VERSION "created by canmatrix"

NS_ :

BS_:

BU_: User ADM_PC_LL25 ADM_PC_BC25 ADM_PC_BP25 ADM_PC_BI25

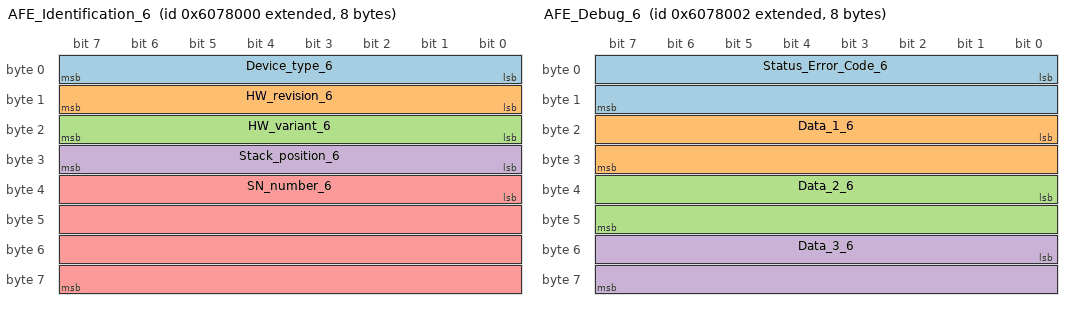
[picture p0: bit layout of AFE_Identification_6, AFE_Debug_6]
BO_ 2248638464 AFE_Identification_6: 8 ADM_PC_BP25
 SG_ Device_type_6 : 0|8@1+ (1,0) [0|255] "" Vector__XXX
 SG_ HW_revision_6 : 8|8@1+ (1,0) [0|255] "" Vector__XXX
 SG_ HW_variant_6 : 16|8@1+ (1,0) [0|255] "" Vector__XXX
 SG_ Stack_position_6 : 24|8@1+ (1,0) [0|255] "" Vector__XXX
 SG_ SN_number_6 : 32|32@1+ (1,0) [0|4294967295] "" Vector__XXX

BO_ 2248638465 AFE_FwInfo_6: 8 ADM_PC_BP25
 SG_ FW_info_mux_6 M : 56|8@1+ (1,0) [0|255] "" Vector__XXX
 SG_ FW_revision_0_6 m0 : 0|8@1+ (1,0) [0|255] "" Vector__XXX
 SG_ FW_revision_1_6 m0 : 8|8@1+ (1,0) [0|255] "" Vector__XXX
 SG_ FW_revision_2_6 m0 : 16|8@1+ (1,0) [0|255] "" Vector__XXX
 SG_ FW_revision_3_6 m0 : 24|8@1+ (1,0) [0|255] "" Vector__XXX
 SG_ FW_revision_4_6 m0 : 32|8@1+ (1,0) [0|255] "" Vector__XXX
 SG_ FW_revision_5_6 m0 : 40|8@1+ (1,0) [0|255] "" Vector__XXX
 SG_ FW_revision_6_6 m0 : 48|8@1+ (1,0) [0|255] "" Vector__XXX
 SG_ FW_revision_7_6 m1 : 0|8@1+ (1,0) [0|255] "" Vector__XXX
 SG_ FW_revision_8_6 m1 : 8|8@1+ (1,0) [0|255] "" Vector__XXX
 SG_ FW_revision_9_6 m1 : 16|8@1+ (1,0) [0|255] "" Vector__XXX
 SG_ FW_revision_10_6 m1 : 24|8@1+ (1,0) [0|255] "" Vector__XXX
 SG_ FW_revision_11_6 m1 : 32|8@1+ (1,0) [0|255] "" Vector__XXX
 SG_ FW_revision_12_6 m1 : 40|8@1+ (1,0) [0|255] "" Vector__XXX
 SG_ FW_revision_13_6 m1 : 48|8@1+ (1,0) [0|255] "" Vector__XXX
 SG_ FW_datecode_0_6 m2 : 0|8@1+ (1,0) [0|255] "" Vector__XXX
 SG_ FW_datecode_1_6 m2 : 8|8@1+ (1,0) [0|255] "" Vector__XXX
 SG_ FW_datecode_2_6 m2 : 16|8@1+ (1,0) [0|255] "" Vector__XXX
 SG_ FW_datecode_3_6 m2 : 24|8@1+ (1,0) [0|255] "" Vector__XXX
 SG_ FW_datecode_4_6 m2 : 32|8@1+ (1,0) [0|255] "" Vector__XXX
 SG_ FW_datecode_5_6 m2 : 40|8@1+ (1,0) [0|255] "" Vector__XXX
 SG_ FW_datecode_6_6 m2 : 48|8@1+ (1,0) [0|255] "" Vector__XXX
 SG_ FW_datecode_7_6 m3 : 0|8@1+ (1,0) [0|255] "" Vector__XXX
 SG_ FW_datecode_8_6 m3 : 8|8@1+ (1,0) [0|255] "" Vector__XXX
 SG_ FW_datecode_9_6 m3 : 16|8@1+ (1,0) [0|255] "" Vector__XXX
 SG_ FW_datecode_10_6 m3 : 24|8@1+ (1,0) [0|255] "" Vector__XXX
 SG_ FW_datecode_11_6 m3 : 32|8@1+ (1,0) [0|255] "" Vector__XXX
 SG_ FW_datecode_12_6 m3 : 40|8@1+ (1,0) [0|255] "" Vector__XXX
 SG_ FW_datecode_13_6 m3 : 48|8@1+ (1,0) [0|255] "" Vector__XXX

BO_ 2248638477 _AFE_Boot_FwInfo_6: 8 ADM_PC_BP25
 SG_ Boot_FW_info_mux_6 M : 56|8@1+ (1,0) [0|255] "" Vector__XXX
 SG_ FW_revision_0_6 m0 : 0|8@1+ (1,0) [0|255] "" Vector__XXX
 SG_ FW_revision_1_6 m0 : 8|8@1+ (1,0) [0|255] "" Vector__XXX
 SG_ FW_revision_2_6 m0 : 16|8@1+ (1,0) [0|255] "" Vector__XXX
 SG_ FW_revision_3_6 m0 : 24|8@1+ (1,0) [0|255] "" Vector__XXX
 SG_ FW_revision_4_6 m0 : 32|8@1+ (1,0) [0|255] "" Vector__XXX
 SG_ FW_revision_5_6 m0 : 40|8@1+ (1,0) [0|255] "" Vector__XXX
 SG_ FW_revision_6_6 m0 : 48|8@1+ (1,0) [0|255] "" Vector__XXX
 SG_ FW_revision_7_6 m1 : 0|8@1+ (1,0) [0|255] "" Vector__XXX
 SG_ FW_revision_8_6 m1 : 8|8@1+ (1,0) [0|255] "" Vector__XXX
 SG_ FW_revision_9_6 m1 : 16|8@1+ (1,0) [0|255] "" Vector__XXX
 SG_ FW_revision_10_6 m1 : 24|8@1+ (1,0) [0|255] "" Vector__XXX
 SG_ FW_revision_11_6 m1 : 32|8@1+ (1,0) [0|255] "" Vector__XXX
 SG_ FW_revision_12_6 m1 : 40|8@1+ (1,0) [0|255] "" Vector__XXX
 SG_ FW_revision_13_6 m1 : 48|8@1+ (1,0) [0|255] "" Vector__XXX
 SG_ FW_datecode_0_6 m2 : 0|8@1+ (1,0) [0|255] "" Vector__XXX
 SG_ FW_datecode_1_6 m2 : 8|8@1+ (1,0) [0|255] "" Vector__XXX
 SG_ FW_datecode_2_6 m2 : 16|8@1+ (1,0) [0|255] "" Vector__XXX
 SG_ FW_datecode_3_6 m2 : 24|8@1+ (1,0) [0|255] "" Vector__XXX
 SG_ FW_datecode_4_6 m2 : 32|8@1+ (1,0) [0|255] "" Vector__XXX
 SG_ FW_datecode_5_6 m2 : 40|8@1+ (1,0) [0|255] "" Vector__XXX
 SG_ FW_datecode_6_6 m2 : 48|8@1+ (1,0) [0|255] "" Vector__XXX
 SG_ FW_datecode_7_6 m3 : 0|8@1+ (1,0) [0|255] "" Vector__XXX
 SG_ FW_datecode_8_6 m3 : 8|8@1+ (1,0) [0|255] "" Vector__XXX
 SG_ FW_datecode_9_6 m3 : 16|8@1+ (1,0) [0|255] "" Vector__XXX
 SG_ FW_datecode_10_6 m3 : 24|8@1+ (1,0) [0|255] "" Vector__XXX
 SG_ FW_datecode_11_6 m3 : 32|8@1+ (1,0) [0|255] "" Vector__XXX
 SG_ FW_datecode_12_6 m3 : 40|8@1+ (1,0) [0|255] "" Vector__XXX
 SG_ FW_datecode_13_6 m3 : 48|8@1+ (1,0) [0|255] "" Vector__XXX

BO_ 2248638466 AFE_Debug_6: 8 ADM_PC_BP25
 SG_ Status_Error_Code_6 : 0|16@1+ (1,0) [0|65535] "" Vector__XXX
 SG_ Data_1_6 : 16|16@1+ (1,0) [0|65535] "" Vector__XXX
 SG_ Data_2_6 : 32|16@1+ (1,0) [0|65535] "" Vector__XXX
 SG_ Data_3_6 : 48|16@1+ (1,0) [0|65535] "" Vector__XXX

BO_ 2248638471 AFE_Status_6: 8 ADM_PC_BP25
 SG_ Running_6 : 0|1@1+ (1,0) [0|1] "" Vector__XXX
 SG_ PWM_6 : 1|1@1+ (1,0) [0|1] "" Vector__XXX
 SG_ Current_dc_loop_mode_6 : 2|1@1+ (1,0) [0|1] "" Vector__XXX
 SG_ Current_ac_loop_mode_6 : 3|1@1+ (1,0) [0|1] "" Vector__XXX
 SG_ Buck_6 : 5|1@1+ (1,0) [0|1] "" Vector__XXX
 SG_ Boost_6 : 6|1@1+ (1,0) [0|1] "" Vector__XXX
 SG_ Precharge_dc_buck_mode_6 : 7|1@1+ (1,0) [0|1] "" Vector__XXX
 SG_ Precharge_dc_boost_mode_6 : 8|1@1+ (1,0) [0|1] "" Vector__XXX
 SG_ Rectifier_3ph_6 : 9|1@1+ (1,0) [0|1] "" Vector__XXX
 SG_ Stack_mode_6 : 10|1@1+ (1,0) [0|1] "" Vector__XXX
 SG_ Master_6 : 11|1@1+ (1,0) [0|1] "" Vector__XXX
 SG_ Slave_6 : 12|1@1+ (1,0) [0|1] "" Vector__XXX
 SG_ Inverter_1ph_6 : 13|1@1+ (1,0) [0|1] "" Vector__XXX
 SG_ Boost_Neutral_6 : 14|1@1+ (1,0) [0|1] "" Vector__XXX
 SG_ Rectifier_1ph_6 : 15|1@1+ (1,0) [0|1] "" Vector__XXX
 SG_ Inverter_3ph_6 : 16|1@1+ (1,0) [0|1] "" Vector__XXX
 SG_ Ready_6 : 17|1@1+ (1,0) [0|1] "" Vector__XXX
 SG_ Inverter_1ph_Sync_6 : 18|1@1+ (1,0) [0|1] "" Vector__XXX
 SG_ Neutral_6 : 19|1@1+ (1,0) [0|1] "" Vector__XXX
 SG_ Rectifier_1ph_Buck_6 : 20|1@1+ (1,0) [0|1] "" Vector__XXX
 SG_ Inverter_1ph_Boost_6 : 21|1@1+ (1,0) [0|1] "" Vector__XXX
 SG_ Rectifier_distributed_6 : 22|1@1+ (1,0) [0|1] "" Vector__XXX
 SG_ MPPT_buck_6 : 23|1@1+ (1,0) [0|1] "" Vector__XXX
 SG_ MPPT_boost_6 : 24|1@1+ (1,0) [0|1] "" Vector__XXX
 SG_ Buck_2p_float_6 : 25|1@1+ (1,0) [0|1] "" Vector__XXX
 SG_ Inverter_1ph_Distributed_6 : 26|1@1+ (1,0) [0|1] "" Vector__XXX

BO_ 2248638470 AFE_Faults_6: 3 ADM_PC_BP25
 SG_ Protection_trip_internal_6 : 0|1@1+ (1,0) [0|1] "" Vector__XXX
 SG_ Protection_trip_external_6 : 1|1@1+ (1,0) [0|1] "" Vector__XXX
 SG_ Phase_U_overcurrent_6 : 2|1@1+ (1,0) [0|1] "" Vector__XXX
 SG_ Phase_U_overvoltage_6 : 3|1@1+ (1,0) [0|1] "" Vector__XXX
 SG_ Phase_U_undervoltage_6 : 4|1@1+ (1,0) [0|1] "" Vector__XXX
 SG_ Phase_V_overvoltage_6 : 5|1@1+ (1,0) [0|1] "" Vector__XXX
 SG_ Phase_V_undervoltage_6 : 6|1@1+ (1,0) [0|1] "" Vector__XXX
 SG_ Phase_V_overcurrent_6 : 7|1@1+ (1,0) [0|1] "" Vector__XXX
 SG_ Phase_W_overvoltage_6 : 8|1@1+ (1,0) [0|1] "" Vector__XXX
 SG_ Phase_W_undervoltage_6 : 9|1@1+ (1,0) [0|1] "" Vector__XXX
 SG_ Phase_W_overcurrent_6 : 10|1@1+ (1,0) [0|1] "" Vector__XXX
 SG_ DC_undervoltage_6 : 11|1@1+ (1,0) [0|1] "" Vector__XXX
 SG_ DC_overvoltage_6 : 12|1@1+ (1,0) [0|1] "" Vector__XXX
 SG_ MOSFET_overtemperature_6 : 13|1@1+ (1,0) [0|1] "" Vector__XXX
 SG_ Inductor_overtemperature_6 : 14|1@1+ (1,0) [0|1] "" Vector__XXX
 SG_ Keep_Alive_not_served_6 : 15|1@1+ (1,0) [0|1] "" Vector__XXX
 SG_ PLL_not_locked_6 : 16|1@1+ (1,0) [0|1] "" Vector__XXX
 SG_ NFO_6 : 20|1@1+ (1,0) [0|1] "" Vector__XXX
 SG_ Measurement_system_failure_6 : 21|1@1+ (1,0) [0|1] "" Vector__XXX
 SG_ EEPROM_failure_6 : 22|1@1+ (1,0) [0|1] "" Vector__XXX
 SG_ System_6 : 23|1@1+ (1,0) [0|1] "" Vector__XXX

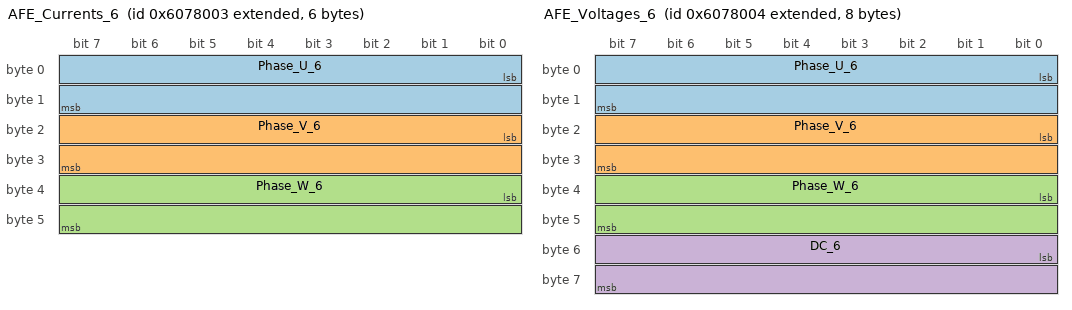
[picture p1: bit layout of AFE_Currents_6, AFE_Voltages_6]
BO_ 2248638467 AFE_Currents_6: 6 ADM_PC_BP25
 SG_ Phase_U_6 : 0|16@1- (0.01,0) [-327.68|327.67] "A" Vector__XXX
 SG_ Phase_V_6 : 16|16@1- (0.01,0) [-327.68|327.67] "A" Vector__XXX
 SG_ Phase_W_6 : 32|16@1- (0.01,0) [-327.68|327.67] "A" Vector__XXX

BO_ 2248638480 AFE_DC_Bus_current_6: 2 ADM_PC_BP25
 SG_ Bus_current_6 : 0|16@1- (0.01,0) [-327.68|327.67] "A" Vector__XXX

BO_ 2248638478 _AFE_Broadcast_6: 8 ADM_PC_BP25
 SG_ Diagnostics_Index_6 M : 56|8@1+ (1,0) [0|255] "" Vector__XXX
 SG_ Phase_U_6 m1 : 8|16@1- (0.01,0) [-327.68|327.67] "A" ADM_PC_BP25
 SG_ Phase_V_6 m1 : 24|16@1- (0.01,0) [-327.68|327.67] "A" ADM_PC_BP25
 SG_ Phase_W_6 m1 : 40|16@1- (0.01,0) [-327.68|327.67] "A" ADM_PC_BP25
 SG_ Stack_position_6 : 0|5@1+ (1,0) [0|31] "" ADM_PC_BP25
 SG_ Group_ID_6 : 5|3@1+ (1,0) [0|7] "" ADM_PC_BP25

BO_ 2248638468 AFE_Voltages_6: 8 ADM_PC_BP25
 SG_ Phase_U_6 : 0|16@1- (0.1,0) [-3276.8|3276.7] "V" Vector__XXX
 SG_ Phase_V_6 : 16|16@1- (0.1,0) [-3276.8|3276.7] "V" Vector__XXX
 SG_ Phase_W_6 : 32|16@1- (0.1,0) [-3276.8|3276.7] "V" Vector__XXX
 SG_ DC_6 : 48|16@1- (0.1,0) [-3276.8|3276.7] "V" Vector__XXX

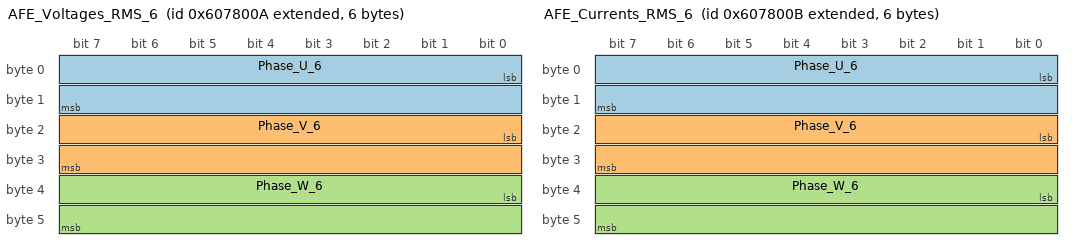
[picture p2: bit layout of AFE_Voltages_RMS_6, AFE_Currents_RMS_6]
BO_ 2248638474 AFE_Voltages_RMS_6: 6 ADM_PC_BP25
 SG_ Phase_U_6 : 0|16@1+ (0.1,0) [0|6553.5] "V" Vector__XXX
 SG_ Phase_V_6 : 16|16@1+ (0.1,0) [0|6553.5] "V" Vector__XXX
 SG_ Phase_W_6 : 32|16@1+ (0.1,0) [0|6553.5] "V" Vector__XXX

BO_ 2248638475 AFE_Currents_RMS_6: 6 ADM_PC_BP25
 SG_ Phase_U_6 : 0|16@1+ (0.01,0) [0.00|655.35] "A" Vector__XXX
 SG_ Phase_V_6 : 16|16@1+ (0.01,0) [0.00|655.35] "A" Vector__XXX
 SG_ Phase_W_6 : 32|16@1+ (0.01,0) [0.00|655.35] "A" Vector__XXX

BO_ 2248638476 AFE_Mains_6: 4 ADM_PC_BP25
 SG_ Frequency_6 : 0|16@1+ (0.01,0) [0.00|655.35] "Hz" Vector__XXX
 SG_ Phase_6 : 16|16@1- (0.1,0) [-3276.8|3276.7] "Deg." Vector__XXX

BO_ 2248638469 AFE_Temperatures_6: 4 ADM_PC_BP25
 SG_ Temp_Bridge_6 : 0|16@1- (0.01,0) [-327.68|327.67] "°C" Vector__XXX
 SG_ Temp_Inductors_6 : 16|16@1- (0.01,0) [-327.68|327.67] "°C" Vector__XXX

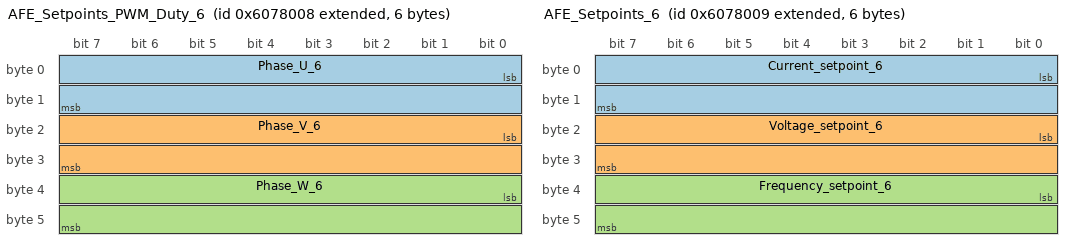
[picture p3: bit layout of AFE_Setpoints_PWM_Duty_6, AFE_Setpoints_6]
BO_ 2248638472 AFE_Setpoints_PWM_Duty_6: 6 ADM_PC_BP25
 SG_ Phase_U_6 : 0|16@1+ (0.001525902,0) [0E-009|99.999987570] "%" Vector__XXX
 SG_ Phase_V_6 : 16|16@1+ (0.001525902,0) [0E-009|99.999987570] "%" Vector__XXX
 SG_ Phase_W_6 : 32|16@1+ (0.001525902,0) [0E-009|99.999987570] "%" Vector__XXX

BO_ 2248638473 AFE_Setpoints_6: 6 ADM_PC_BP25
 SG_ Current_setpoint_6 : 0|16@1- (0.01,0) [-327.68|327.67] "A" Vector__XXX
 SG_ Voltage_setpoint_6 : 16|16@1+ (0.1,0) [0|6553.5] "V" Vector__XXX
 SG_ Frequency_setpoint_6 : 32|16@1+ (0.01,0) [0.00|655.35] "Hz" Vector__XXX

BO_ 2248605792 AFE_Keep_Alive_6: 1 User
 SG_ Keep_Alive_Enable_6 : 0|1@1+ (1,0) [0|1] "" ADM_PC_BP25

BO_ 2248605760 AFE_Mode_Control_6: 8 User
 SG_ Converter_ON_6 : 0|1@1+ (1,0) [0|1] "" ADM_PC_BP25
 SG_ PWM_ON_6 : 1|1@1+ (1,0) [0|1] "" ADM_PC_BP25
 SG_ DC_Current_feedback_ON_6 : 2|1@1+ (1,0) [0|1] "" ADM_PC_BP25
 SG_ AC_Current_feedback_ON_6 : 3|1@1+ (1,0) [0|1] "" ADM_PC_BP25
 SG_ Buck_ON_6 : 5|1@1+ (1,0) [0|1] "" ADM_PC_BP25
 SG_ Boost_ON_6 : 6|1@1+ (1,0) [0|1] "" ADM_PC_BP25
 SG_ Rectifier_3ph_ON_6 : 9|1@1+ (1,0) [0|1] "" ADM_PC_BP25
 SG_ Inverter_1ph_ON_6 : 10|1@1+ (1,0) [0|1] "" ADM_PC_BP25
 SG_ Rectifier_1ph_ON_6 : 11|1@1+ (1,0) [0|1] "" ADM_PC_BP25
 SG_ Boost_Neutral_ON_6 : 12|1@1+ (1,0) [0|1] "" ADM_PC_BP25
 SG_ Inverter_3ph_ON_6 : 13|1@1+ (1,0) [0|1] "" ADM_PC_BP25
 SG_ Inverter_1ph_Sync_ON_6 : 14|1@1+ (1,0) [0|1] "" ADM_PC_BP25
 SG_ Neutral_ON_6 : 15|1@1+ (1,0) [0|1] "" ADM_PC_BP25
 SG_ Rectifier_1ph_Buck_ON_6 : 16|1@1+ (1,0) [0|1] "" ADM_PC_BP25
 SG_ Inverter_1ph_Boost_ON_6 : 17|1@1+ (1,0) [0|1] "" ADM_PC_BP25
 SG_ Rectifier_Distributed_ON_6 : 18|1@1+ (1,0) [0|1] "" ADM_PC_BP25
 SG_ MPPT_buck_ON_6 : 19|1@1+ (1,0) [0|1] "" ADM_PC_BP25
 SG_ MPPT_boost_ON_6 : 20|1@1+ (1,0) [0|1] "" ADM_PC_BP25
 SG_ Buck_2p_float_ON_6 : 21|1@1+ (1,0) [0|1] "" ADM_PC_BP25
 SG_ Inverter_1ph_Distributed_ON_6 : 22|1@1+ (1,0) [0|1] "" ADM_PC_BP25

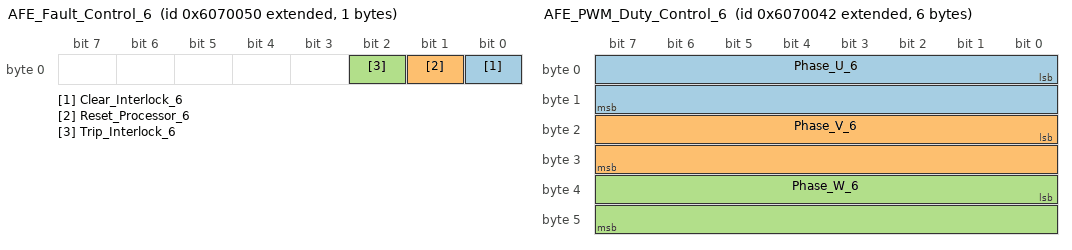
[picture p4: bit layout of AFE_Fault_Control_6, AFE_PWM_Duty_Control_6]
BO_ 2248605776 AFE_Fault_Control_6: 1 User
 SG_ Clear_Interlock_6 : 0|1@1+ (1,0) [0|1] "" ADM_PC_BP25
 SG_ Reset_Processor_6 : 1|1@1+ (1,0) [0|1] "" ADM_PC_BP25
 SG_ Trip_Interlock_6 : 2|1@1+ (1,0) [0|1] "" ADM_PC_BP25

BO_ 2248605761 AFE_Reactive_Current_Setpoint_Co: 2 User
 SG_ Reactive_current_setpoint_6 : 0|16@1- (0.01,0) [-150|150] "A" ADM_PC_BP25

BO_ 2248605762 AFE_PWM_Duty_Control_6: 6 User
 SG_ Phase_U_6 : 0|16@1+ (0.001525902,0) [0E-009|99.999987570] "%" ADM_PC_BP25
 SG_ Phase_V_6 : 16|16@1+ (0.001525902,0) [0E-009|99.999987570] "%" ADM_PC_BP25
 SG_ Phase_W_6 : 32|16@1+ (0.001525902,0) [0E-009|99.999987570] "%" ADM_PC_BP25

BO_ 2248605763 AFE_Current_Setpoint_Control_6: 2 User
 SG_ Current_setpoint_6 : 0|16@1- (0.01,0) [-150|150] "A" ADM_PC_BP25

BO_ 2248605764 AFE_Voltage_Setpoint_Control_6: 2 User
 SG_ Voltage_setpoint_6 : 0|16@1+ (0.1,0) [0|1500] "V" ADM_PC_BP25

BO_ 2248605768 AFE_Frequency_Setpoint_Control_6: 2 User
 SG_ Frequency_setpoint_6 : 0|16@1+ (0.01,0) [40|70] "Hz" ADM_PC_BP25

BO_ 2248605769 AFE_Phase_Setpoint_Control_6: 2 User
 SG_ Phase_setpoint_6 : 0|16@1+ (1,0) [0|360] "deg" ADM_PC_BP25

BO_ 2248605808 AFE_Rectifier_Setpoint_Control_6: 8 User
 SG_ Voltage_setpoint_2_6 : 0|16@1+ (0.1,0) [0|1500] "V" ADM_PC_BP25
 SG_ Current_setpoint_2_6 : 16|16@1- (0.01,0) [-150|150] "A" ADM_PC_BP25

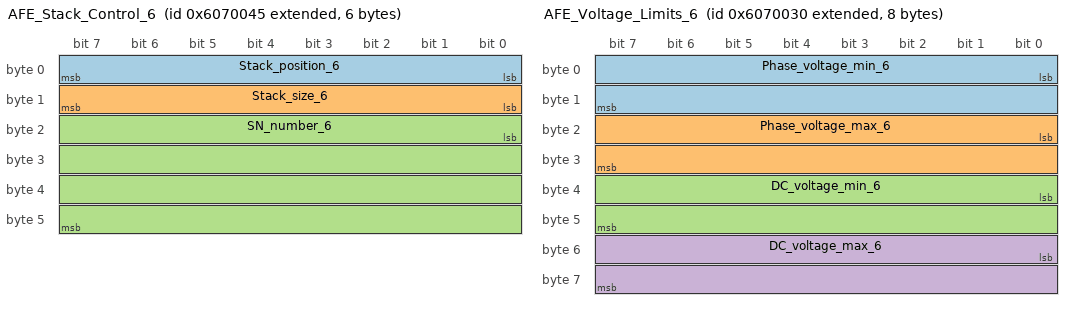
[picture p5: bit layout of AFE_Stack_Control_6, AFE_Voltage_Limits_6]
BO_ 2248605765 AFE_Stack_Control_6: 6 User
 SG_ Stack_position_6 : 0|8@1+ (1,0) [0|255] "" ADM_PC_BP25
 SG_ Stack_size_6 : 8|8@1+ (1,0) [0|255] "" ADM_PC_BP25
 SG_ SN_number_6 : 16|32@1+ (1,0) [0|4294967295] "" ADM_PC_BP25

BO_ 2248605744 AFE_Voltage_Limits_6: 8 User
 SG_ Phase_voltage_min_6 : 0|16@1- (0.1,0) [0|3276.7] "V" ADM_PC_BP25
 SG_ Phase_voltage_max_6 : 16|16@1- (0.1,0) [-3276.8|850] "V" ADM_PC_BP25
 SG_ DC_voltage_min_6 : 32|16@1- (0.1,0) [0|3276.7] "V" ADM_PC_BP25
 SG_ DC_voltage_max_6 : 48|16@1- (0.1,0) [-3276.8|850] "V" ADM_PC_BP25

BO_ 2248605745 AFE_Current_Limits_6: 4 User
 SG_ Phase_current_min_6 : 0|16@1- (0.01,0) [-60|60] "A" ADM_PC_BP25
 SG_ Phase_current_max_6 : 16|16@1- (0.01,0) [-60|60] "A" ADM_PC_BP25

BO_ 2248605772 AFE_Group_Control_6: 1 User
 SG_ Group_ID_6 : 0|8@1+ (1,0) [0|255] "" ADM_PC_BP25

BO_ 2248638479 AFE_Group_Info_6: 1 ADM_PC_BP25
 SG_ Group_ID_6 : 0|8@1+ (1,0) [0|255] "" Vector__XXX

BO_ 2248605793 AFE_System_Flags_Control_6: 8 User
 SG_ Factory_mode_6 : 0|1@1+ (1,0) [0|1] "" ADM_PC_BP25
 SG_ Silent_CAN_mode_6 : 1|1@1+ (1,0) [0|1] "" ADM_PC_BP25

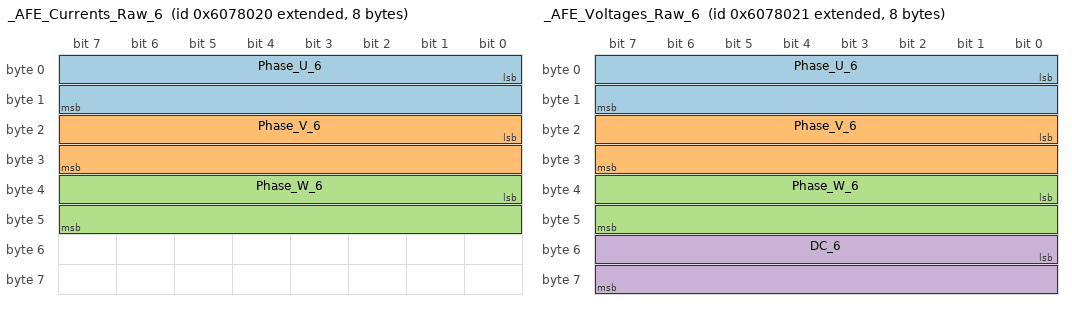
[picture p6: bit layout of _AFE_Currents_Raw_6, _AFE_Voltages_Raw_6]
BO_ 2248638496 _AFE_Currents_Raw_6: 8 ADM_PC_BP25
 SG_ Phase_U_6 : 0|16@1- (1,0) [-32768|32767] "" Vector__XXX
 SG_ Phase_V_6 : 16|16@1- (1,0) [-32768|32767] "" Vector__XXX
 SG_ Phase_W_6 : 32|16@1- (1,0) [-32768|32767] "" Vector__XXX

BO_ 2248638497 _AFE_Voltages_Raw_6: 8 ADM_PC_BP25
 SG_ Phase_U_6 : 0|16@1- (1,0) [-32768|32767] "" Vector__XXX
 SG_ Phase_V_6 : 16|16@1- (1,0) [-32768|32767] "" Vector__XXX
 SG_ Phase_W_6 : 32|16@1- (1,0) [-32768|32767] "" Vector__XXX
 SG_ DC_6 : 48|16@1- (1,0) [-32768|32767] "" Vector__XXX

BO_ 2248605770 _AFE_ADC_Calibration_Mode_6: 1 User
 SG_ Calibration_Index_6 M : 2|5@1+ (1,0) [0|31] "" Vector__XXX
 SG_ Current_U_6 m1 : 0|2@1+ (1,0) [0|3] "" ADM_PC_BP25
 SG_ Current_V_6 m2 : 0|2@1+ (1,0) [0|3] "" ADM_PC_BP25
 SG_ Current_W_6 m3 : 0|2@1+ (1,0) [0|3] "" ADM_PC_BP25
 SG_ Voltage_U_6 m4 : 0|2@1+ (1,0) [0|3] "" ADM_PC_BP25
 SG_ Voltage_V_6 m5 : 0|2@1+ (1,0) [0|3] "" ADM_PC_BP25
 SG_ Voltage_W_6 m6 : 0|2@1+ (1,0) [0|3] "" ADM_PC_BP25
 SG_ Voltage_DC_6 m7 : 0|2@1+ (1,0) [0|3] "" ADM_PC_BP25
 SG_ start_6 : 7|1@1+ (1,0) [0|1] "" ADM_PC_BP25

BO_ 2248605771 _AFE_ADC_Calibration_Setpoint_6: 3 User
 SG_ Calibration_Index_6 M : 16|5@1+ (1,0) [0|31] "" Vector__XXX
 SG_ Current_U_6 m1 : 0|16@1- (0.01,0) [-100|100] "A" ADM_PC_BP25
 SG_ Current_V_6 m2 : 0|16@1- (0.01,0) [-100|100] "A" ADM_PC_BP25
 SG_ Current_W_6 m3 : 0|16@1- (0.01,0) [-100|100] "A" ADM_PC_BP25
 SG_ Voltage_U_6 m4 : 0|16@1+ (0.1,0) [0|1500] "V" ADM_PC_BP25
 SG_ Voltage_V_6 m5 : 0|16@1+ (0.1,0) [0|1500] "V" ADM_PC_BP25
 SG_ Voltage_W_6 m6 : 0|16@1+ (0.1,0) [0|1500] "V" ADM_PC_BP25
 SG_ Voltage_DC_6 m7 : 0|16@1+ (0.1,0) [0|1500] "V" ADM_PC_BP25
 SG_ point_6 : 21|3@1+ (1,0) [0|7] "" ADM_PC_BP25

BO_ 2248605766 _AFE_Calibration_Offset_Update_6: 6 User
 SG_ Calibration_Index_6 M : 16|16@1+ (1,0) [0|65535] "" Vector__XXX
 SG_ Current_U_6 m0 : 0|16@1- (1,0) [-32768|32767] "ADC Counts" ADM_PC_BP25
 SG_ Current_V_6 m1 : 0|16@1- (1,0) [-32768|32767] "ADC Counts" ADM_PC_BP25
 SG_ Current_W_6 m2 : 0|16@1- (1,0) [-32768|32767] "ADC Counts" ADM_PC_BP25
 SG_ Voltage_U_6 m3 : 0|16@1- (1,0) [-32768|32767] "ADC Counts" ADM_PC_BP25
 SG_ Voltage_V_6 m4 : 0|16@1- (1,0) [-32768|32767] "ADC Counts" ADM_PC_BP25
 SG_ Voltage_W_6 m5 : 0|16@1- (1,0) [-32768|32767] "ADC Counts" ADM_PC_BP25
 SG_ Voltage_DC_6 m6 : 0|16@1- (1,0) [-32768|32767] "ADC Counts" ADM_PC_BP25
 SG_ CRC_6 : 32|16@1+ (1,0) [0|65535] "-" ADM_PC_BP25

BO_ 2248605767 _AFE_Calibration_Scale_Update_6: 6 User
 SG_ Calibration_Index_6 M : 16|16@1+ (1,0) [0|65535] "" Vector__XXX
 SG_ Current_U_6 m0 : 0|16@1- (0.0000152587890625,0) [-0.5000000000000000|0.4999847412109375] "scale = 1.0 + value" ADM_PC_BP25
 SG_ Current_V_6 m1 : 0|16@1- (0.0000152587890625,0) [-0.5000000000000000|0.4999847412109375] "scale = 1.0 + value" ADM_PC_BP25
 SG_ Current_W_6 m2 : 0|16@1- (0.0000152587890625,0) [-0.5000000000000000|0.4999847412109375] "scale = 1.0 + value" ADM_PC_BP25
 SG_ Voltage_U_6 m3 : 0|16@1- (0.0000152587890625,0) [-0.5000000000000000|0.4999847412109375] "scale = 1.0 + value" ADM_PC_BP25
 SG_ Voltage_V_6 m4 : 0|16@1- (0.0000152587890625,0) [-0.5000000000000000|0.4999847412109375] "scale = 1.0 + value" ADM_PC_BP25
 SG_ Voltage_W_6 m5 : 0|16@1- (0.0000152587890625,0) [-0.5000000000000000|0.4999847412109375] "scale = 1.0 + value" ADM_PC_BP25
 SG_ Voltage_DC_6 m6 : 0|16@1- (0.0000152587890625,0) [-0.5000000000000000|0.4999847412109375] "scale = 1.0 + value" ADM_PC_BP25
 SG_ CRC_6 : 32|16@1+ (1,0) [0|65535] "-" ADM_PC_BP25

BO_ 2248638545 _AFE_Calibration_Adc_Scale_6: 6 ADM_PC_BP25
 SG_ Adc_Index_6 M : 32|16@1+ (1,0) [0|65535] "" Vector__XXX
 SG_ Current_U_6 m0 : 0|32@1+ (1,0) [0|4294967295] "1 / adc_bins" User
 SG_ Current_V_6 m1 : 0|32@1+ (1,0) [0|4294967295] "1 / adc_bins" User
 SG_ Current_W_6 m2 : 0|32@1+ (1,0) [0|4294967295] "1 / adc_bins" User
 SG_ Voltage_U_6 m3 : 0|32@1+ (1,0) [0|4294967295] "1 / adc_bins" User
 SG_ Voltage_V_6 m4 : 0|32@1+ (1,0) [0|4294967295] "1 / adc_bins" User
 SG_ Voltage_W_6 m5 : 0|32@1+ (1,0) [0|4294967295] "1 / adc_bins" User
 SG_ Voltage_DC_6 m6 : 0|32@1+ (1,0) [0|4294967295] "1 / adc_bins" User

BO_ 2248638546 _AFE_Calibration_Adc_Fs_6: 6 ADM_PC_BP25
 SG_ Adc_Index_6 M : 32|16@1+ (1,0) [0|65535] "" Vector__XXX
 SG_ Current_U_6 m0 : 0|32@1+ (1,0) [0|4294967295] "Fullscale" User
 SG_ Current_V_6 m1 : 0|32@1+ (1,0) [0|4294967295] "Fullscale" User
 SG_ Current_W_6 m2 : 0|32@1+ (1,0) [0|4294967295] "Fullscale" User
 SG_ Voltage_U_6 m3 : 0|32@1+ (1,0) [0|4294967295] "Fullscale" User
 SG_ Voltage_V_6 m4 : 0|32@1+ (1,0) [0|4294967295] "Fullscale" User
 SG_ Voltage_W_6 m5 : 0|32@1+ (1,0) [0|4294967295] "Fullscale" User
 SG_ Voltage_DC_6 m6 : 0|32@1+ (1,0) [0|4294967295] "Fullscale" User

BO_ 2248638547 _AFE_Calibration_Adc_Offset_6: 4 ADM_PC_BP25
 SG_ Adc_Index_6 M : 16|16@1+ (1,0) [0|65535] "" Vector__XXX
 SG_ Current_U_6 m0 : 0|16@1- (1,0) [-32768|32767] "-" User
 SG_ Current_V_6 m1 : 0|16@1- (1,0) [-32768|32767] "-" User
 SG_ Current_W_6 m2 : 0|16@1- (1,0) [-32768|32767] "-" User
 SG_ Voltage_U_6 m3 : 0|16@1- (1,0) [-32768|32767] "-" User
 SG_ Voltage_V_6 m4 : 0|16@1- (1,0) [-32768|32767] "-" User
 SG_ Voltage_W_6 m5 : 0|16@1- (1,0) [-32768|32767] "-" User
 SG_ Voltage_DC_6 m6 : 0|16@1- (1,0) [-32768|32767] "-" User

BO_ 2248638548 _AFE_Calibration_Adc_Gain_6: 4 ADM_PC_BP25
 SG_ Adc_Index_6 M : 16|16@1+ (1,0) [0|65535] "" Vector__XXX
 SG_ Current_U_6 m0 : 0|16@1- (1,0) [-32768|32767] "-" User
 SG_ Current_V_6 m1 : 0|16@1- (1,0) [-32768|32767] "-" User
 SG_ Current_W_6 m2 : 0|16@1- (1,0) [-32768|32767] "-" User
 SG_ Voltage_U_6 m3 : 0|16@1- (1,0) [-32768|32767] "-" User
 SG_ Voltage_V_6 m4 : 0|16@1- (1,0) [-32768|32767] "-" User
 SG_ Voltage_W_6 m5 : 0|16@1- (1,0) [-32768|32767] "-" User
 SG_ Voltage_DC_6 m6 : 0|16@1- (1,0) [-32768|32767] "-" User

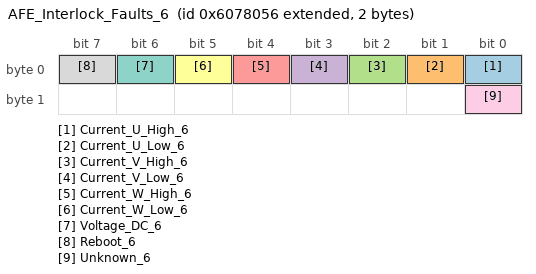
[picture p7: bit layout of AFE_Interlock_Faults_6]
BO_ 2248638550 AFE_Interlock_Faults_6: 2 ADM_PC_BP25
 SG_ Current_U_High_6 : 0|1@1+ (1,0) [0|1] "" Vector__XXX
 SG_ Current_U_Low_6 : 1|1@1+ (1,0) [0|1] "" Vector__XXX
 SG_ Current_V_High_6 : 2|1@1+ (1,0) [0|1] "" Vector__XXX
 SG_ Current_V_Low_6 : 3|1@1+ (1,0) [0|1] "" Vector__XXX
 SG_ Current_W_High_6 : 4|1@1+ (1,0) [0|1] "" Vector__XXX
 SG_ Current_W_Low_6 : 5|1@1+ (1,0) [0|1] "" Vector__XXX
 SG_ Voltage_DC_6 : 6|1@1+ (1,0) [0|1] "" Vector__XXX
 SG_ Reboot_6 : 7|1@1+ (1,0) [0|1] "" Vector__XXX
 SG_ Unknown_6 : 8|1@1+ (1,0) [0|1] "" Vector__XXX

BO_TX_BU_ 2248605760 : User,ADM_PC_LL25,ADM_PC_BC25,ADM_PC_BI25;
BO_TX_BU_ 2248605763 : User,ADM_PC_LL25,ADM_PC_BC25,ADM_PC_BI25;
BO_TX_BU_ 2248605764 : User,ADM_PC_LL25,ADM_PC_BC25,ADM_PC_BI25;
CM_ BO_ 2248638464  "Identification of the device";
CM_ BO_ 2248638465  "Git revision of the DSP firmware";
CM_ BO_ 2248638477  "Git revision of the bootloader firmware.";
CM_ BO_ 2248638466  "Values for debugging of HW/SW problems";
CM_ BO_ 2248638471  "Status bitfield";
CM_ BO_ 2248638470  "Fault bitfield";
CM_ BO_ 2248638467  "Current of phases U, V, W";
CM_ BO_ 2248638480  "Current of of the DC Bus";
CM_ BO_ 2248638478  "All AFEs will listen to this message";
CM_ BO_ 2248638475  "RMS Current of phases U, V, W";
CM_ BO_ 2248638476  "Three-Phase mains health (frequency, phase...)";
CM_ BO_ 2248638469  "Readouts of the module temperature sensors";
CM_ BO_ 2248638472  "Setpoints";
CM_ BO_ 2248638473  "Setpoints";
CM_ BO_ 2248605792  "Keep alive ping message. ";
CM_ BO_ 2248605760  "Operation Mode control: sets the converter operation mode";
CM_ BO_ 2248605776  "Fault Control: actions to clear faults and reset the system";
CM_ BO_ 2248605761  "Reactive power setpoint control.";
CM_ BO_ 2248605762  "PWM duty cycle control";
CM_ BO_ 2248605763  "Current setpoint control";
CM_ BO_ 2248605764  "Voltage setpoint control";
CM_ BO_ 2248605768  "Frequency setpoint control";
CM_ BO_ 2248605769  "Phase setpoint control";
CM_ BO_ 2248605808  "Additional voltage and current setpoints in single-phase rectifier and inverter control modes.";
CM_ BO_ 2248605765  "PFC stack control";
CM_ BO_ 2248605744  "Set the input and output voltage limits (minimum and maximum)";
CM_ BO_ 2248605745  "Set the output current limits (mminimum and maximum)";
CM_ BO_ 2248605772  "Set the Group ID of the device";
CM_ BO_ 2248638479  "Contains the Group ID of the device";
CM_ BO_ 2248605793  "Control the system flags";
CM_ BO_ 2248638496  "Current of phases A and B";
CM_ BO_ 2248638497  "Current of phases A and B";
CM_ BO_ 2248605770  "Automatic ADC calibration.";
CM_ BO_ 2248605771  "Setpoint for automatic ADC calibration.";
CM_ BO_ 2248605766  "Update of the calibration table for offsets.";
CM_ BO_ 2248605767  "Update of the calibration table for scales.";
CM_ BO_ 2248638545  "
                Adc scale (resolution) value of readouts.
            ";
CM_ BO_ 2248638546  "
                Adc fullscale value of readouts.
            ";
CM_ BO_ 2248638547  "
                Readout of ADC calibration data (offset) from EEPROM.
            ";
CM_ BO_ 2248638548  "
                Readout of ADC calibration data (gain) from EEPROM.
            ";
CM_ BO_ 2248638550  "Fault bitfield";

CM_ SG_ 2248638464 Device_type_6 "The device identification field, uniquely identifies the sender in the network";
CM_ SG_ 2248638464 HW_revision_6 "The hardware revision number";
CM_ SG_ 2248638464 HW_variant_6 "The DSP firmware revision number";
CM_ SG_ 2248638464 Stack_position_6 "Position of the module within the stack";
CM_ SG_ 2248638464 SN_number_6 "Unique module serial number";
CM_ SG_ 2248638465 FW_revision_0_6 "Character 0";
CM_ SG_ 2248638465 FW_revision_1_6 "Character 1";
CM_ SG_ 2248638465 FW_revision_2_6 "Character 2";
CM_ SG_ 2248638465 FW_revision_3_6 "Character 3";
CM_ SG_ 2248638465 FW_revision_4_6 "Character 3";
CM_ SG_ 2248638465 FW_revision_5_6 "Character 3";
CM_ SG_ 2248638465 FW_revision_6_6 "Character 3";
CM_ SG_ 2248638465 FW_revision_7_6 "Character 7";
CM_ SG_ 2248638465 FW_revision_8_6 "Character 8";
CM_ SG_ 2248638465 FW_revision_9_6 "Character 9";
CM_ SG_ 2248638465 FW_revision_10_6 "Character 10";
CM_ SG_ 2248638465 FW_revision_11_6 "Character 11";
CM_ SG_ 2248638465 FW_revision_12_6 "Character 12";
CM_ SG_ 2248638465 FW_revision_13_6 "Character 13";
CM_ SG_ 2248638465 FW_datecode_0_6 "Character 0";
CM_ SG_ 2248638465 FW_datecode_1_6 "Character 1";
CM_ SG_ 2248638465 FW_datecode_2_6 "Character 2";
CM_ SG_ 2248638465 FW_datecode_3_6 "Character 3";
CM_ SG_ 2248638465 FW_datecode_4_6 "Character 3";
CM_ SG_ 2248638465 FW_datecode_5_6 "Character 3";
CM_ SG_ 2248638465 FW_datecode_6_6 "Character 3";
CM_ SG_ 2248638465 FW_datecode_7_6 "Character 7";
CM_ SG_ 2248638465 FW_datecode_8_6 "Character 8";
CM_ SG_ 2248638465 FW_datecode_9_6 "Character 9";
CM_ SG_ 2248638465 FW_datecode_10_6 "Character 10";
CM_ SG_ 2248638465 FW_datecode_11_6 "Character 11";
CM_ SG_ 2248638465 FW_datecode_12_6 "Character 12";
CM_ SG_ 2248638465 FW_datecode_13_6 "Character 13";
CM_ SG_ 2248638477 FW_revision_0_6 "Character 0";
CM_ SG_ 2248638477 FW_revision_1_6 "Character 1";
CM_ SG_ 2248638477 FW_revision_2_6 "Character 2";
CM_ SG_ 2248638477 FW_revision_3_6 "Character 3";
CM_ SG_ 2248638477 FW_revision_4_6 "Character 3";
CM_ SG_ 2248638477 FW_revision_5_6 "Character 3";
CM_ SG_ 2248638477 FW_revision_6_6 "Character 3";
CM_ SG_ 2248638477 FW_revision_7_6 "Character 7";
CM_ SG_ 2248638477 FW_revision_8_6 "Character 8";
CM_ SG_ 2248638477 FW_revision_9_6 "Character 9";
CM_ SG_ 2248638477 FW_revision_10_6 "Character 10";
CM_ SG_ 2248638477 FW_revision_11_6 "Character 11";
CM_ SG_ 2248638477 FW_revision_12_6 "Character 12";
CM_ SG_ 2248638477 FW_revision_13_6 "Character 13";
CM_ SG_ 2248638477 FW_datecode_0_6 "Character 0";
CM_ SG_ 2248638477 FW_datecode_1_6 "Character 1";
CM_ SG_ 2248638477 FW_datecode_2_6 "Character 2";
CM_ SG_ 2248638477 FW_datecode_3_6 "Character 3";
CM_ SG_ 2248638477 FW_datecode_4_6 "Character 3";
CM_ SG_ 2248638477 FW_datecode_5_6 "Character 3";
CM_ SG_ 2248638477 FW_datecode_6_6 "Character 3";
CM_ SG_ 2248638477 FW_datecode_7_6 "Character 7";
CM_ SG_ 2248638477 FW_datecode_8_6 "Character 8";
CM_ SG_ 2248638477 FW_datecode_9_6 "Character 9";
CM_ SG_ 2248638477 FW_datecode_10_6 "Character 10";
CM_ SG_ 2248638477 FW_datecode_11_6 "Character 11";
CM_ SG_ 2248638477 FW_datecode_12_6 "Character 12";
CM_ SG_ 2248638477 FW_datecode_13_6 "Character 13";
CM_ SG_ 2248638466 Status_Error_Code_6 "Main status / error code as defined in errno/errno.h";
CM_ SG_ 2248638466 Data_1_6 "Additional information for the error/status";
CM_ SG_ 2248638466 Data_2_6 "Additional information for the error/status";
CM_ SG_ 2248638466 Data_3_6 "Additional information for the error/status";
CM_ SG_ 2248638471 Running_6 "Indicates if converter is running.";
CM_ SG_ 2248638471 PWM_6 "Indicates if converter is in PWM control mode.";
CM_ SG_ 2248638471 Current_dc_loop_mode_6 "Indicates if the current DC loop is enabled.";
CM_ SG_ 2248638471 Current_ac_loop_mode_6 "Indicates if the current AC loop is enabled.";
CM_ SG_ 2248638471 Buck_6 "Indicates if converter is in buck control mode.";
CM_ SG_ 2248638471 Boost_6 "Indicates if converter is in boost control mode.";
CM_ SG_ 2248638471 Precharge_dc_buck_mode_6 "Indicates if the precharge DC mode is enabled - buck direction.";
CM_ SG_ 2248638471 Precharge_dc_boost_mode_6 "Indicates if the precharge DC mode is enabled - boost direction.";
CM_ SG_ 2248638471 Rectifier_3ph_6 "Indicates if converter is in three-phase rectifier control mode.";
CM_ SG_ 2248638471 Stack_mode_6 "Indicates if converter is operating in stack mode.";
CM_ SG_ 2248638471 Master_6 "Indicates if converter is master in the stack.";
CM_ SG_ 2248638471 Slave_6 "Indicates if converter is slave in the stack.";
CM_ SG_ 2248638471 Inverter_1ph_6 "Indicates if converter is in single-phase inverter control mode.";
CM_ SG_ 2248638471 Boost_Neutral_6 "Indicates if converter is in boost control mode with neutral generation.";
CM_ SG_ 2248638471 Rectifier_1ph_6 "Indicates if converter is in single-phase rectifier control mode.";
CM_ SG_ 2248638471 Inverter_3ph_6 "Indicates if converter is in three-phase inverter control mode.";
CM_ SG_ 2248638471 Ready_6 "Indicates if converter is ready for operation.";
CM_ SG_ 2248638471 Inverter_1ph_Sync_6 "Single-phase inverter control mode with phase synchronization.";
CM_ SG_ 2248638471 Neutral_6 "Open-loop neutral generation.";
CM_ SG_ 2248638471 Rectifier_1ph_Buck_6 "Single-phase rectifier with buck on one leg.";
CM_ SG_ 2248638471 Inverter_1ph_Boost_6 "Single-phase inverter with boost on one leg.";
CM_ SG_ 2248638471 Rectifier_distributed_6 "Not available at the moment";
CM_ SG_ 2248638471 MPPT_buck_6 "Not available at the moment";
CM_ SG_ 2248638471 MPPT_boost_6 "Not available at the moment";
CM_ SG_ 2248638471 Buck_2p_float_6 "Buck in phases L1 and L2. Phase L3 is left floating (high impedance)";
CM_ SG_ 2248638471 Inverter_1ph_Distributed_6 "Single-phase inverter mode  distributed";
CM_ SG_ 2248638470 Protection_trip_internal_6 "This flagg is asserted if the interlock is open due to an internal fault condition (self-protection)";
CM_ SG_ 2248638470 Protection_trip_external_6 "This flag is asserted if the interlock is open due to an external condition received in the module.";
CM_ SG_ 2248638470 Phase_U_overcurrent_6 "Indicates an overcurrent event on Phase U. The overcurrent event is triggered when the measured phase current is over the programmed current limit.";
CM_ SG_ 2248638470 Phase_U_overvoltage_6 "Indicates an overvoltage event on Phase U. The overvoltage event is triggered when the measured phase voltage is over the programmed voltage limit.";
CM_ SG_ 2248638470 Phase_U_undervoltage_6 "Indicates an undervoltage event on Phase U. The overvoltage event is triggered when the measured phase voltage is over the programmed voltage limit.";
CM_ SG_ 2248638470 Phase_V_overvoltage_6 "Indicates an overvoltage event on Phase V. The overvoltage event is triggered when the measured phase voltage is over the programmed voltage limit.";
CM_ SG_ 2248638470 Phase_V_undervoltage_6 "Indicates an undervoltage event on Phase U. The overvoltage event is triggered when the measured phase voltage is over the programmed voltage limit.";
CM_ SG_ 2248638470 Phase_V_overcurrent_6 "Indicates an overcurrent event on Phase U. The overcurrent event is triggered when the measured phase current is over the programmed current limit.";
CM_ SG_ 2248638470 Phase_W_overvoltage_6 "Indicates an overvoltage event on Phase U. The overvoltage event is triggered when the measured phase voltage is over the programmed voltage limit.";
CM_ SG_ 2248638470 Phase_W_undervoltage_6 "Indicates an undervoltage event on Phase U. The overvoltage event is triggered when the measured phase voltage is over the programmed voltage limit.";
CM_ SG_ 2248638470 Phase_W_overcurrent_6 "Indicates an overcurrent event on Phase U. The overcurrent event is triggered when the measured phase current is over the programmed current limit.";
CM_ SG_ 2248638470 DC_undervoltage_6 "DC bus undervoltage condition. The undervoltage condition is asserted when the measured dc bus voltage is under the programmed voltage limit.";
CM_ SG_ 2248638470 DC_overvoltage_6 "DC bus overvoltage condition. The overvoltage condition is asserted when the measured dc bus voltage is over the programmed voltage limit.";
CM_ SG_ 2248638470 MOSFET_overtemperature_6 "This flag is asserted when the temperature of the MOSFET block is too high.";
CM_ SG_ 2248638470 Inductor_overtemperature_6 "This flag is asserted when the temperature of the inductor block is too high.";
CM_ SG_ 2248638470 Keep_Alive_not_served_6 "The Keep Alive feature is enabled but it was not served with the periodic message.";
CM_ SG_ 2248638470 PLL_not_locked_6 "Flag asserted when in rectifier modes, the PLL went out of lock condition";
CM_ SG_ 2248638470 Measurement_system_failure_6 "The voltages/currents measurement system is malfunctionning, and readouts are not guaranteed to be accurate.";
CM_ SG_ 2248638470 EEPROM_failure_6 "The configuration EEPROM failed to load or save the module configuration.";
CM_ SG_ 2248638467 Phase_U_6 "Phase current is the MOSFET loop current, in the branch U of the converter.";
CM_ SG_ 2248638467 Phase_V_6 "Phase current is the MOSFET loop current, in the branch V of the converter.";
CM_ SG_ 2248638467 Phase_W_6 "Phase current is the MOSFET loop current, in the branch W of the converter.";
CM_ SG_ 2248638480 Bus_current_6 "DC Bus current is possitive when current goes from input to output";
CM_ SG_ 2248638478 Phase_U_6 "Phase current is the MOSFET loop current, in the branch U of the converter.";
CM_ SG_ 2248638478 Phase_V_6 "Phase current is the MOSFET loop current, in the branch V of the converter.";
CM_ SG_ 2248638478 Phase_W_6 "Phase current is the MOSFET loop current, in the branch W of the converter.";
CM_ SG_ 2248638478 Stack_position_6 "Sender Stack position";
CM_ SG_ 2248638478 Group_ID_6 "Sender Group ID";
CM_ SG_ 2248638475 Phase_U_6 "RMS Phase current is the MOSFET loop current, in the branch U of the converter.";
CM_ SG_ 2248638475 Phase_V_6 "RMS Phase current is the MOSFET loop current, in the branch V of the converter.";
CM_ SG_ 2248638475 Phase_W_6 "RMS Phase current is the MOSFET loop current, in the branch W of the converter.";
CM_ SG_ 2248638476 Frequency_6 "Frequency of Three-Phase system";
CM_ SG_ 2248638476 Phase_6 "Phase of Three-Phase system";
CM_ SG_ 2248638469 Temp_Bridge_6 "Temperature of the MOSFET block";
CM_ SG_ 2248638469 Temp_Inductors_6 "Temperature of the inductors";
CM_ SG_ 2248638472 Phase_U_6 "The actual PWM duty cycle setpoint";
CM_ SG_ 2248638472 Phase_V_6 "The actual PWM duty cycle setpoint";
CM_ SG_ 2248638472 Phase_W_6 "The actual PWM duty cycle setpoint";
CM_ SG_ 2248638473 Current_setpoint_6 "The actual current setpoint";
CM_ SG_ 2248638473 Voltage_setpoint_6 "The actual voltage setpoint";
CM_ SG_ 2248638473 Frequency_setpoint_6 "The actual frequency setpoint";
CM_ SG_ 2248605792 Keep_Alive_Enable_6 "If set to 1, module will expect to receive this message every second repeatedly, or it will stop operation";
CM_ SG_ 2248605760 Converter_ON_6 "Enable the converter.";
CM_ SG_ 2248605760 PWM_ON_6 "Enable the PWM control mode.";
CM_ SG_ 2248605760 DC_Current_feedback_ON_6 "Enable the DC current loop";
CM_ SG_ 2248605760 AC_Current_feedback_ON_6 "Enable the AC current loop";
CM_ SG_ 2248605760 Buck_ON_6 "Enable the buck control mode.";
CM_ SG_ 2248605760 Boost_ON_6 "Enable the boost control mode.";
CM_ SG_ 2248605760 Rectifier_3ph_ON_6 "Enable the three-phase rectifier control mode.";
CM_ SG_ 2248605760 Inverter_1ph_ON_6 "Enable the single-phase inverter control mode.";
CM_ SG_ 2248605760 Rectifier_1ph_ON_6 "Enable the single-phase rectifier control mode.";
CM_ SG_ 2248605760 Boost_Neutral_ON_6 "Enable the boost control mode with neutral generation.";
CM_ SG_ 2248605760 Inverter_3ph_ON_6 "Enable the three-phase inverter control mode.";
CM_ SG_ 2248605760 Inverter_1ph_Sync_ON_6 "Single-phase inverter control mode with phase synchronization.";
CM_ SG_ 2248605760 Neutral_ON_6 "Open-loop neutral generation.";
CM_ SG_ 2248605760 Rectifier_1ph_Buck_ON_6 "Single-phase rectifier with buck on one leg.";
CM_ SG_ 2248605760 Inverter_1ph_Boost_ON_6 "Single-phase inverter with boost on one leg.";
CM_ SG_ 2248605760 Rectifier_Distributed_ON_6 "Single-phase (floating) distributed rectifier";
CM_ SG_ 2248605760 MPPT_buck_ON_6 "MPPT buck";
CM_ SG_ 2248605760 MPPT_boost_ON_6 "MPPT boost";
CM_ SG_ 2248605760 Buck_2p_float_ON_6 "Boost on L1 and L2. Floating L3 (high-impedance)";
CM_ SG_ 2248605760 Inverter_1ph_Distributed_ON_6 "Single-phase inverter mode distributed";
CM_ SG_ 2248605776 Clear_Interlock_6 "Clears the converter interlock";
CM_ SG_ 2248605776 Reset_Processor_6 "Reset the converter DSP";
CM_ SG_ 2248605776 Trip_Interlock_6 "Trip the inetrnal Interlock";
CM_ SG_ 2248605761 Reactive_current_setpoint_6 "This defines reactive current setpoint for 3-phase rectifier mode";
CM_ SG_ 2248605762 Phase_U_6 "The actual PWM duty cycle setpoint";
CM_ SG_ 2248605762 Phase_V_6 "The actual PWM duty cycle setpoint";
CM_ SG_ 2248605762 Phase_W_6 "The actual PWM duty cycle setpoint";
CM_ SG_ 2248605763 Current_setpoint_6 "Sets the output current setpoint. Active only when the current loop is enabled";
CM_ SG_ 2248605764 Voltage_setpoint_6 "Sets the output voltage setpoint. Active only when the voltage loop is enabled";
CM_ SG_ 2248605768 Frequency_setpoint_6 "Sets the frequency for single-phase and three-phase generator modes.";
CM_ SG_ 2248605769 Phase_setpoint_6 "Sets the phase for inverter control modes.";
CM_ SG_ 2248605765 Stack_position_6 "The converter position within the stack";
CM_ SG_ 2248605765 Stack_size_6 "How many PFC converters are in stack in total";
CM_ SG_ 2248605765 SN_number_6 "Unique module serial number";
CM_ SG_ 2248605744 Phase_voltage_min_6 "Minimum tolerated phase voltage";
CM_ SG_ 2248605744 Phase_voltage_max_6 "Maximum allowable phase voltage";
CM_ SG_ 2248605744 DC_voltage_min_6 "Minimum allowable dc voltage";
CM_ SG_ 2248605744 DC_voltage_max_6 "Maximum allowable dc voltage";
CM_ SG_ 2248605745 Phase_current_min_6 "Minimum allowable output current";
CM_ SG_ 2248605745 Phase_current_max_6 "Maximum allowable output current";
CM_ SG_ 2248605772 Group_ID_6 "Desired group ID for the device";
CM_ SG_ 2248638479 Group_ID_6 "Group ID of the device";
CM_ SG_ 2248605793 Factory_mode_6 "Customers MUST NOT USE this bit. If set to 1, module will enter in factory mode. ";
CM_ SG_ 2248605793 Silent_CAN_mode_6 "Customers MUST NOT USE this bit. If set to 1, module will enter in factory mode. ";
CM_ SG_ 2248605770 start_6 "Start automatic calibration. Multiplexer index must be 0!";
CM_ SG_ 2248605771 point_6 "Calibration point index.";
CM_ SG_ 2248605766 CRC_6 "Checksum of bytes 0 to 3, CRC-CCITT, corresponding to qChecksum (www.qt.io)";
CM_ SG_ 2248605767 CRC_6 "Checksum of bytes 0 to 3, CRC-CCITT, corresponding to qChecksum (www.qt.io)";
CM_ SG_ 2248638550 Current_U_High_6 "This flag is set if a hight current on U tripped the internal interlock";
CM_ SG_ 2248638550 Current_U_Low_6 "This flag is set if a low current on U tripped the internal interlock";
CM_ SG_ 2248638550 Current_V_High_6 "This flag is set if a hight current on V tripped the internal interlock";
CM_ SG_ 2248638550 Current_V_Low_6 "This flag is set if a low current on V tripped the internal interlock";
CM_ SG_ 2248638550 Current_W_High_6 "This flag is set if a hight current on W tripped the internal interlock";
CM_ SG_ 2248638550 Current_W_Low_6 "This flag is set if a low current on W tripped the internal interlock";
CM_ SG_ 2248638550 Voltage_DC_6 "This flag is set if a voltage on DC tripped the internal interlock";
CM_ SG_ 2248638550 Reboot_6 "This flag is set if a reboot tripped the internal interlock";
CM_ SG_ 2248638550 Unknown_6 "This flag the reason for the internal interlock is unknown";

BA_DEF_ BO_ "SystemMessageLongSymbol" STRING;

BA_ "SystemMessageLongSymbol" BO_ 2248605761 "AFE_Reactive_Current_Setpoint_Control_6";

VAL_ 2248638464 Device_type_6 7 "AFE";
VAL_ 2248638470 Protection_trip_internal_6 1 "fault";
VAL_ 2248638470 Protection_trip_external_6 1 "fault";
VAL_ 2248638470 Phase_U_overcurrent_6 1 "fault";
VAL_ 2248638470 Phase_U_overvoltage_6 1 "fault";
VAL_ 2248638470 Phase_U_undervoltage_6 1 "fault";
VAL_ 2248638470 Phase_V_overvoltage_6 1 "fault";
VAL_ 2248638470 Phase_V_undervoltage_6 1 "fault";
VAL_ 2248638470 Phase_V_overcurrent_6 1 "fault";
VAL_ 2248638470 Phase_W_overvoltage_6 1 "fault";
VAL_ 2248638470 Phase_W_undervoltage_6 1 "fault";
VAL_ 2248638470 Phase_W_overcurrent_6 1 "fault";
VAL_ 2248638470 DC_undervoltage_6 1 "fault";
VAL_ 2248638470 DC_overvoltage_6 1 "fault";
VAL_ 2248638470 MOSFET_overtemperature_6 1 "fault";
VAL_ 2248638470 Inductor_overtemperature_6 1 "fault";
VAL_ 2248638470 Keep_Alive_not_served_6 1 "fault";
VAL_ 2248638470 PLL_not_locked_6 1 "fault";
VAL_ 2248638470 NFO_6 1 "fault";
VAL_ 2248638470 Measurement_system_failure_6 1 "fault";
VAL_ 2248638470 EEPROM_failure_6 1 "fault";
VAL_ 2248638470 System_6 1 "fault";
VAL_ 2248638550 Current_U_High_6 1 "fault";
VAL_ 2248638550 Current_U_Low_6 1 "fault";
VAL_ 2248638550 Current_V_High_6 1 "fault";
VAL_ 2248638550 Current_V_Low_6 1 "fault";
VAL_ 2248638550 Current_W_High_6 1 "fault";
VAL_ 2248638550 Current_W_Low_6 1 "fault";
VAL_ 2248638550 Voltage_DC_6 1 "fault";
VAL_ 2248638550 Reboot_6 1 "fault";
VAL_ 2248638550 Unknown_6 1 "fault";
SIG_VALTYPE_ 2248638545 Current_U_6 : 1;
SIG_VALTYPE_ 2248638545 Current_V_6 : 1;
SIG_VALTYPE_ 2248638545 Current_W_6 : 1;
SIG_VALTYPE_ 2248638545 Voltage_U_6 : 1;
SIG_VALTYPE_ 2248638545 Voltage_V_6 : 1;
SIG_VALTYPE_ 2248638545 Voltage_W_6 : 1;
SIG_VALTYPE_ 2248638545 Voltage_DC_6 : 1;
SIG_VALTYPE_ 2248638546 Current_U_6 : 1;
SIG_VALTYPE_ 2248638546 Current_V_6 : 1;
SIG_VALTYPE_ 2248638546 Current_W_6 : 1;
SIG_VALTYPE_ 2248638546 Voltage_U_6 : 1;
SIG_VALTYPE_ 2248638546 Voltage_V_6 : 1;
SIG_VALTYPE_ 2248638546 Voltage_W_6 : 1;
SIG_VALTYPE_ 2248638546 Voltage_DC_6 : 1;
